# STM32F767 register map
File version: 1.7
CPU: CM7 r0p1, little endian, MPU, FPU, 4 interrupt priority bits
Registers are 32-bit, read-write, reset 0x0 unless marked. A register's access mark holds for its fields unless they carry their own. Offsets are from the block's base; [hi:lo] are bit positions; {n}, {i} and the like mark numbered series; 'fields as' and 'values as' point back to an identical list.

## OTG_FS_PWRCLK — USB on the go full speed
Base 0x50000E00
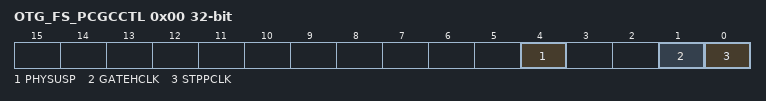
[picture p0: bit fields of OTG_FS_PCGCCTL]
0x00 OTG_FS_PCGCCTL — OTG_FS power and clock gating control register (OTG_FS_PCGCCTL)
  [4] PHYSUSP — PHY Suspended
  [1] GATEHCLK
  [0] STPPCLK — Stop PHY clock

## OTG_HS_PWRCLK — USB on the go high speed
Base 0x40040E00
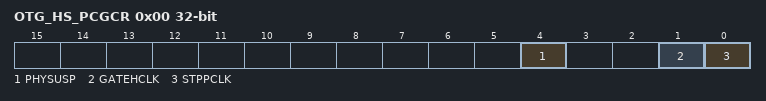
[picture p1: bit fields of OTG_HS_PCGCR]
0x00 OTG_HS_PCGCR — Power and clock gating control register
  [4] PHYSUSP — PHY suspended
  [1] GATEHCLK
  [0] STPPCLK — Stop PHY clock

## DBGMCU — MCU debug component
Base 0xE0042000
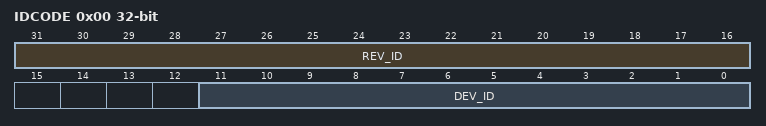
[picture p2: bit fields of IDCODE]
0x00 IDCODE ro — DBGMCU_IDCODE
  [31:16] REV_ID — Revision identifie
  [11:0] DEV_ID — Device identifier

## NVIC — Nested Vectored Interrupt Controller. ARMv7-M allows up to 240 external interrupts, so this is sized to the full architectural maximum: 8 banks of ISER/ICER/ISPR/ICPR/IABR and 60 IPR registers. A real device with fewer implemented interrupts still has this whole address range reserved by the architecture -- it just leaves the trailing registers unimplemented (reads as 0). This matches how CMSIS itself models NVIC_Type generically (ISER[8]/ICER[8]/ISPR[8]/ICPR[8]/IABR[8]/IP[240] in core_cm3.h/core_cm4.h) -- your MCU's own vendor SVD/header will only expose as many IRQn as it actually implements.
Base 0xE000E100
{0x0+4i} ISER{i} (i=0..7) — Interrupt Set-Enable Register
  [31:0] BITS
{0x80+4i} ICER{i} (i=0..7) — Interrupt Clear-Enable Register
  [31:0] BITS
{0x100+4i} ISPR{i} (i=0..7) — Interrupt Set-Pending Register
  [31:0] BITS
{0x180+4i} ICPR{i} (i=0..7) — Interrupt Clear-Pending Register
  [31:0] BITS
{0x200+4i} IABR{i} (i=0..7) ro — Interrupt Active Bit Register
  [31:0] BITS
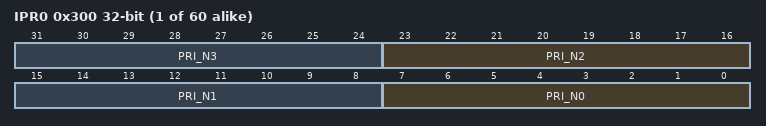
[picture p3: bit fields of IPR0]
{0x300+4i} IPR{i} (i=0..59) — Interrupt Priority Registers 0-59 (cover IRQ0..IRQ239)
  [8n+7:8n] PRI_N{n} (n=0..3) — Priority, byte offset {n}
0xE00 STIR wo — Software Trigger Interrupt Register. Only usable if SCB->CCR.USERSETMPEND allows unprivileged access and the device implements this register.
  [8:0] INTID — Interrupt ID of the interrupt to trigger, 0-239

## MPU — Memory Protection Unit -- OPTIONAL on ARMv7-M (__MPU_PRESENT). When present, includes 3 alias RBAR/RASR pairs so up to 4 regions can be programmed without re-writing RNR each time (verified against CMSIS core_cm3.h/core_cm4.h: MPU_TYPE_RALIASES=4).
Base 0xE000ED90
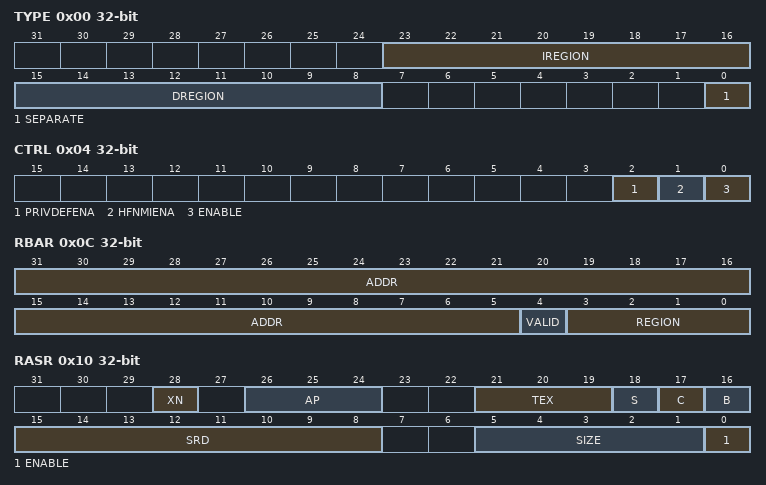
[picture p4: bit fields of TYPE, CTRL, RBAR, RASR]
0x00 TYPE ro — MPU Type Register
  [23:16] IREGION, [15:8] DREGION, [0] SEPARATE
0x04 CTRL — MPU Control Register
  [2] PRIVDEFENA, [1] HFNMIENA, [0] ENABLE
0x08 RNR — MPU Region Number Register
  [7:0] REGION
0x0C RBAR — MPU Region Base Address Register
  [31:5] ADDR, [4] VALID, [3:0] REGION
0x10 RASR — MPU Region Attribute and Size Register
  [28] XN, [26:24] AP, [21:19] TEX, [18] S, [17] C, [16] B, [15:8] SRD, [5:1] SIZE, [0] ENABLE
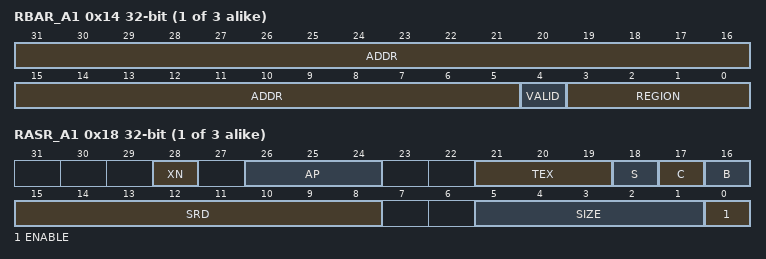
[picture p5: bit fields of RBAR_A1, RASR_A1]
{0xC+8i} RBAR_A{i} (i=1..3) — MPU Region Base Address Register alias
  [31:5] ADDR, [4] VALID, [3:0] REGION
{0x10+8i} RASR_A{i} (i=1..3) — MPU Region Attribute and Size Register alias
  fields as RASR

## SCnSCB — System Control and ID Registers not in the SCB address range: ICTR (Interrupt Controller Type Register) and ACTLR (Auxiliary Control Register). Verified against CMSIS_6 core_cm3.h/core_cm4.h/core_cm7.h.
Base 0xE000E000
0x04 ICTR ro — Interrupt Controller Type Register
  [3:0] INTLINESNUM — (Number of 32-interrupt NVIC banks implemented) - 1: total external interrupts = (INTLINESNUM+1)*32
0x08 ACTLR — Auxiliary Control Register -- wholly IMPLEMENTATION DEFINED by the architecture: bit meanings differ even among Arm's own reference cores (e.g. core_cm3.h defines DISMCYCINT/DISDEFWBUF/DISFOLD; core_cm4.h adds DISFPCA/DISOOFP for its optional FPU; core_cm7.h redefines the whole register around its cache/branch-prediction microarchitecture) -- deliberately left with no fields, same treatment as the ID_* registers above.

## SysTick — SysTick Timer. Identical register set on every Cortex-M core (ARMv6-M through current ARMv8-M).
Base 0xE000E010
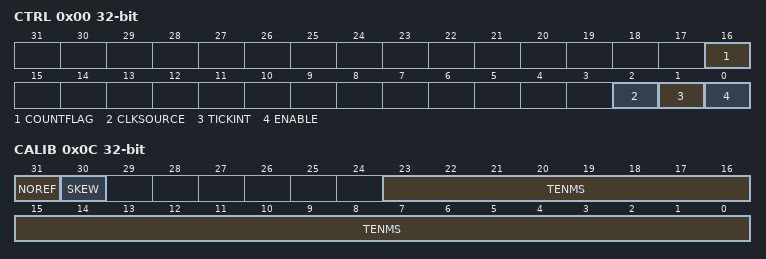
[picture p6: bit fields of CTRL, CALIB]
0x00 CTRL — SysTick Control and Status Register
  [16] COUNTFLAG ro, [2] CLKSOURCE, [1] TICKINT, [0] ENABLE
0x04 LOAD — SysTick Reload Value Register
  [23:0] RELOAD
0x08 VAL — SysTick Current Value Register. Any write clears it to 0 and clears COUNTFLAG.
  [23:0] CURRENT
0x0C CALIB ro — SysTick Calibration Value Register
  [31] NOREF, [30] SKEW, [23:0] TENMS

## DCB — Debug Control Block (DHCSR, DCRSR, DCRDR, DEMCR) -- named "CoreDebug" prior to CMSIS_6, which renamed it to DCB across the whole M-profile line ("CoreDebug"/"CoreDebug_Type" remain as deprecated aliases for the same registers). Fixed ADIv5/CoreSight debug architecture -- identical on every Cortex-M core.
Base 0xE000EDF0
0x00 DHCSR — Debug Halting Control and Status Register
  [25] S_RESET_ST ro
  [24] S_RETIRE_ST ro
  [19] S_LOCKUP ro
  [18] S_SLEEP ro
  [17] S_HALT ro
  [16] S_REGRDY ro
  [31:16] DBGKEY wo — Write 0xA05F to enable write access to bits [15:0]; reads as 0
  [5] C_SNAPSTALL
  [3] C_MASKINTS
  [2] C_STEP
  [1] C_HALT
  [0] C_DEBUGEN
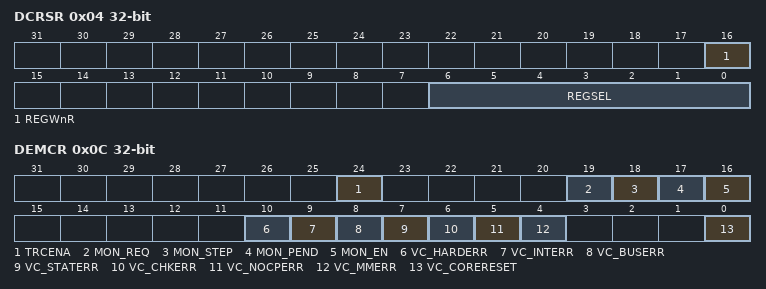
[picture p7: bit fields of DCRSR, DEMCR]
0x04 DCRSR wo — Debug Core Register Selector Register
  [16] REGWnR
  [6:0] REGSEL — Widened from 5 to 7 bits in CMSIS_6
0x08 DCRDR — Debug Core Register Data Register
  [31:0] DBGTMP
0x0C DEMCR — Debug Exception and Monitor Control Register. On ARMv6-M only VC_CORERESET and TRCENA are architecturally defined; the fault-related VC_* bits and the monitor MON_* bits apply from ARMv7-M up (v6-M has no MemManage/BusFault/UsageFault/Debug-Monitor exception, so those control bits do not exist there -- included here for completeness/documentation, treat as reserved on v6-M).
  [24] TRCENA — Trace enable (DWT/ITM/ETM/TPIU) -- only meaningful where those blocks exist
  [19] MON_REQ — Debug Monitor request -- ARMv7-M and later only
  [18] MON_STEP — Debug Monitor step -- ARMv7-M and later only
  [17] MON_PEND — Debug Monitor pend -- ARMv7-M and later only
  [16] MON_EN — Debug Monitor enable -- ARMv7-M and later only
  [10] VC_HARDERR — Debug trap on HardFault exception
  [9] VC_INTERR — Debug trap on interrupt/exception service errors -- ARMv7-M and later only
  [8] VC_BUSERR — Debug trap on BusFault exception -- ARMv7-M and later only
  [7] VC_STATERR — Debug trap on UsageFault state error -- ARMv7-M and later only
  [6] VC_CHKERR — Debug trap on UsageFault caused by checking error -- ARMv7-M and later only
  [5] VC_NOCPERR — Debug trap on UsageFault caused by no coprocessor -- ARMv7-M and later only
  [4] VC_MMERR — Debug trap on MemManage exception -- ARMv7-M and later only
  [0] VC_CORERESET — Reset Vector Catch
